VERSION ""

NS_ :

BS_:

BU_:

BO_ 2183149062 HeadLight_3606: 8 Vector__XXX
 SG_ HeadLightOn : 15|8@0+ (1,0) [0|0] "" Vector__XXX
 SG_ HeadLightSource : 7|8@0+ (1,0) [0|0] "" Vector__XXX

BO_ 2182616582 RearLight_1606: 8 Vector__XXX
 SG_ RearLightOn : 39|8@0+ (1,0) [0|0] "" Vector__XXX
 SG_ RearLightUnknownByte2 : 23|8@0+ (1,0) [0|0] "" Vector__XXX

BO_ 2478269440 Lock_6400: 1 Vector__XXX
 SG_ Unlocked : 7|8@0+ (1,0) [0|0] "" Vector__XXX

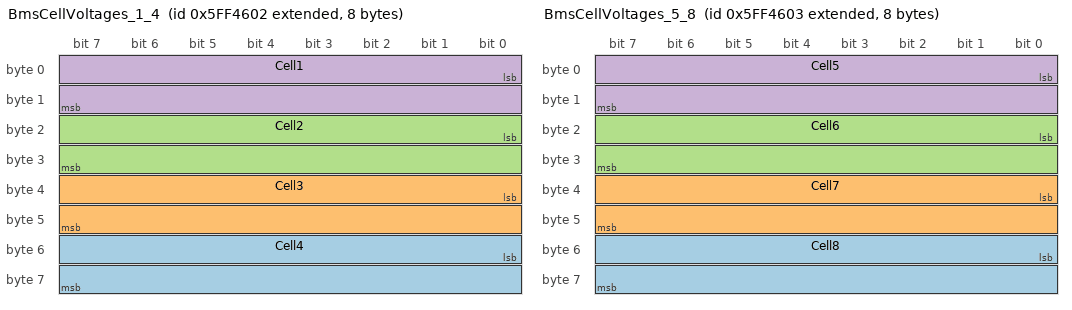
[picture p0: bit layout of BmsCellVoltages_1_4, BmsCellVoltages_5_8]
BO_ 2248099330 BmsCellVoltages_1_4: 8 Vector__XXX
 SG_ Cell4 : 48|16@1+ (1,0) [0|0] "mV" Vector__XXX
 SG_ Cell3 : 32|16@1+ (1,0) [0|0] "mV" Vector__XXX
 SG_ Cell2 : 16|16@1+ (1,0) [0|0] "mV" Vector__XXX
 SG_ Cell1 : 0|16@1+ (1,0) [0|0] "mV" Vector__XXX

BO_ 2248099331 BmsCellVoltages_5_8: 8 Vector__XXX
 SG_ Cell8 : 48|16@1+ (1,0) [0|0] "mV" Vector__XXX
 SG_ Cell7 : 32|16@1+ (1,0) [0|0] "mV" Vector__XXX
 SG_ Cell6 : 16|16@1+ (1,0) [0|0] "mV" Vector__XXX
 SG_ Cell5 : 0|16@1+ (1,0) [0|0] "mV" Vector__XXX

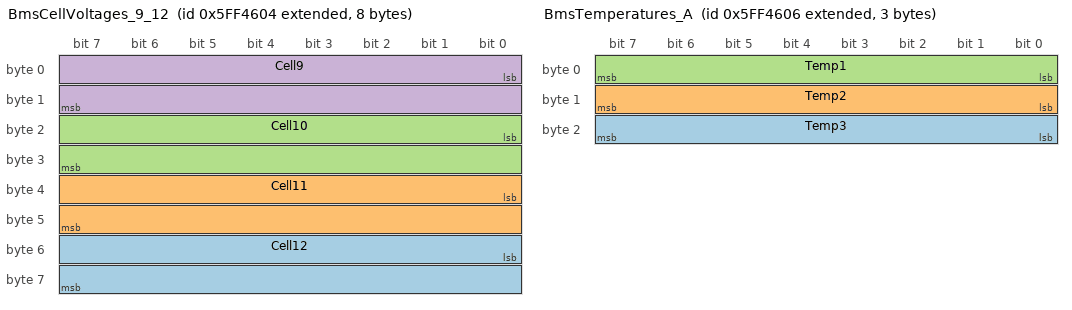
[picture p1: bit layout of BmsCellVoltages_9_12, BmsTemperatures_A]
BO_ 2248099332 BmsCellVoltages_9_12: 8 Vector__XXX
 SG_ Cell12 : 48|16@1+ (1,0) [0|0] "mV" Vector__XXX
 SG_ Cell11 : 32|16@1+ (1,0) [0|0] "mV" Vector__XXX
 SG_ Cell10 : 16|16@1+ (1,0) [0|0] "mV" Vector__XXX
 SG_ Cell9 : 0|16@1+ (1,0) [0|0] "mV" Vector__XXX

BO_ 2248099333 BmsCellVoltage_13: 8 Vector__XXX
 SG_ Cell13 : 0|16@1+ (1,0) [0|0] "mV" Vector__XXX

BO_ 2248099334 BmsTemperatures_A: 3 Vector__XXX
 SG_ Temp3 : 23|8@0+ (1,0) [0|0] "degC" Vector__XXX
 SG_ Temp2 : 15|8@0+ (1,0) [0|0] "degC" Vector__XXX
 SG_ Temp1 : 7|8@0+ (1,0) [0|0] "degC" Vector__XXX

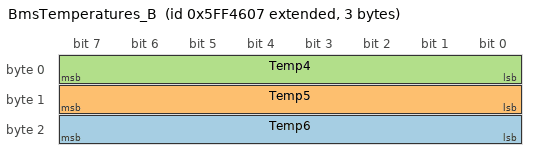
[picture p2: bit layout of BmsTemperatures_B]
BO_ 2248099335 BmsTemperatures_B: 3 Vector__XXX
 SG_ Temp6 : 23|8@0+ (1,0) [0|0] "degC" Vector__XXX
 SG_ Temp5 : 15|8@0+ (1,0) [0|0] "degC" Vector__XXX
 SG_ Temp4 : 7|8@0+ (1,0) [0|0] "degC" Vector__XXX

BO_ 2231317504 Uptime_3400: 8 Vector__XXX
 SG_ Uptime : 23|16@0+ (10,0) [0|0] "s" Vector__XXX

BO_ 2214531072 Heartbeat_1000: 8 Vector__XXX

CM_ BO_ 2183149062 "[confirmed] The headlight. Identified by remote command: the console logged HLON at
1788785214.368 and HLOFF at 1788785234.208, and this message changed 0.77 s and
0.33 s later respectively. Nothing else on the bus changed in either window
except the uptime counter ticking.";
CM_ SG_ 2183149062 HeadLightOn "[confirmed] Byte 1. Goes to 1 within 0.77 s of the HLON command and to 0 within 0.33 s of
HLOFF, then to 1 again 2.0 s after UNLOCK and to 0 1.3 s after LOCK -- so
unlocking the bike switches the headlight on, which is why the periodic GTFRI
report still showed head_light_status=1 after HLOFF. Cross-checks against
<ECU Info> field 5 (Head Light Status) in the same session.";
CM_ SG_ 2183149062 HeadLightSource "[hypothesis] Byte 0 is 0x02 when the change came from an explicit HLON/HLOFF command and
0x01 when it came from the unlock sequence, so it may say what asked for the
change. Two observations of each: nowhere near enough.";
CM_ BO_ 2182616582 "[confirmed] The rear light. Same method as the headlight: RLONEN at 1788785392.364 and
RLOFF at 1788785412.125, with this message changing 0.76 s and 0.40 s later,
and nothing else changing in either window.";
CM_ SG_ 2182616582 RearLightOn "[confirmed] Byte 4. Goes to 1 within 0.76 s of RLONEN and to 0 within 0.40 s of RLOFF, and
also tracks UNLOCK (0.28 s) and LOCK (0.52 s). Cross-checks against <ECU Info>
field 6 (Rear Light Status).";
CM_ SG_ 2182616582 RearLightUnknownByte2 "[hypothesis] Byte 2 is 0x19 (25) while the rear light is on because of an unlock, but 0x00
when it is on because of an RLONEN command. So it is not the light state. A
brightness or mode, possibly. Untested.";
CM_ BO_ 2478269440 "[confirmed] The lock (immobiliser) reporting its state. A single-byte message, and the only
one on the bus with priority 0x13.

Identified across two independent sessions by driving UNLOCK and LOCK remotely
and watching which byte tracked the resulting state. Method: build the lock
state timeline from the +RESP:GTMLS reports, then look for bytes whose value
sets are disjoint between locked and unlocked intervals. Exactly one byte
qualified across 2 locked and 2 unlocked intervals.

CONFIRMED BY DISCONNECTION: a third session was recorded with the HubLock
disabled. This identifier went from 139 frames to zero, and it was the ONLY
identifier to disappear -- 95 identifiers became 94, with none appearing in its
place. Both lamps still toggled normally in that session, so the bus was
healthy and the remote commands were still being processed. The component that
sends this is therefore the HubLock, and AA=0x64 is its address.

NOT the battery lock. <ECU Info> field 13 (Battery-Lock State) stayed 0 through
all three sessions while this byte flipped.";
CM_ SG_ 2478269440 Unlocked "[confirmed] Byte 0. 1 = unlocked, 0 = locked -- note this is the inverse of GTFRI's
ECU Lock State field, so it reads as an \"unlocked\" flag. Named for what the
raw value means rather than inverting it here.

Six transitions across two sessions, every one following its command:
  UNLOCK -> 1 after 2.12 s, 2.55 s, 2.17 s
  LOCK   -> 0 after 0.32 s, 0.46 s, 0.58 s
The asymmetry is consistent and worth keeping: unlocking takes about four times
as long as locking, which is what a motorised latch does and is not what a
command echo would do.

Repeated UNLOCK commands on an already-unlocked bike produce no transition, so
this byte reports actual state and not command receipt. That is why session 2's
six UNLOCK commands yielded only two unlock transitions.

DO NOT use GTFRI's ECU Lock State as a substitute for this signal. With the
HubLock disabled and no 13B76400 on the bus at all, that field still reported
lock_state flipping 0 and 1, so it tracks what the IoT module believes rather
than what the lock did.";
CM_ BO_ 2248099330 "[confirmed] BMS cell voltages, cells 1-4. Confirmed without guesswork: the +RESP:GTBMI
report relays this frame's payload verbatim -- the identical byte string
1410191019101910 appears both in the CAN payload and in the report -- and
GTBMI states a cell count of 13, which is exactly what 05FF4602 through
05FF4605 supply (4+4+4+1). The 13 cells sum to 53.622 V against the 53.696 V
that GTFRI reported for the pack at the same moment, a 0.14 % difference.";
CM_ SG_ 2248099330 Cell4 "[confirmed] Little-endian uint16 in mV.";
CM_ SG_ 2248099330 Cell3 "[confirmed] Little-endian uint16 in mV.";
CM_ SG_ 2248099330 Cell2 "[confirmed] Little-endian uint16 in mV.";
CM_ SG_ 2248099330 Cell1 "[confirmed] Little-endian uint16 in mV: bytes 14 10 read as 0x1014 = 4116 mV.";
CM_ BO_ 2248099331 "[confirmed] BMS cell voltages, cells 5-8. Relayed verbatim in +RESP:GTBMI.";
CM_ SG_ 2248099331 Cell8 "[confirmed] Little-endian uint16 in mV.";
CM_ SG_ 2248099331 Cell7 "[confirmed] Little-endian uint16 in mV.";
CM_ SG_ 2248099331 Cell6 "[confirmed] Little-endian uint16 in mV.";
CM_ SG_ 2248099331 Cell5 "[confirmed] Little-endian uint16 in mV.";
CM_ BO_ 2248099332 "[confirmed] BMS cell voltages, cells 9-12. Relayed verbatim in +RESP:GTBMI.";
CM_ SG_ 2248099332 Cell12 "[confirmed] Little-endian uint16 in mV.";
CM_ SG_ 2248099332 Cell11 "[confirmed] Little-endian uint16 in mV.";
CM_ SG_ 2248099332 Cell10 "[confirmed] Little-endian uint16 in mV.";
CM_ SG_ 2248099332 Cell9 "[confirmed] Little-endian uint16 in mV.";
CM_ BO_ 2248099333 "[confirmed] BMS cell voltage, cell 13, then padding. This pack has 13 cells, so the last
frame of the series carries one value and six zero bytes -- which is how the
cell count was established.";
CM_ SG_ 2248099333 Cell13 "[confirmed] Little-endian uint16 in mV. Bytes 2-7 are always zero: only 13 cells.";
CM_ BO_ 2248099334 "[probable] BMS temperatures. Payload 1C1C1C reads as 28, 28, 28 which is a plausible cell
temperature in degrees Celsius, and the same byte string is relayed in
+RESP:GTBMI immediately after the cell voltage frames. Which physical sensor
each byte is has not been established: <ECU Info> field 12 lists cell maximum,
cell minimum, MOS and \"other\" temperatures, and there are more of those than
there are bytes here.";
CM_ SG_ 2248099334 Temp3 "[probable] 0x1C = 28 degC. Sensor identity unknown.";
CM_ SG_ 2248099334 Temp2 "[probable] 0x1C = 28 degC. Sensor identity unknown.";
CM_ SG_ 2248099334 Temp1 "[probable] 0x1C = 28 degC. Sensor identity unknown; the scale may also have an offset.";
CM_ BO_ 2248099335 "[probable] More BMS temperatures: 1D1B1C reads as 29, 27, 28 degC, and is likewise
relayed verbatim in +RESP:GTBMI. The spread across the two frames is 27-29 degC
on a stationary bike at room temperature, which is what makes the reading
plausible.";
CM_ SG_ 2248099335 Temp6 "[probable] 0x1C = 28 degC. Sensor identity unknown.";
CM_ SG_ 2248099335 Temp5 "[probable] 0x1B = 27 degC. Sensor identity unknown.";
CM_ SG_ 2248099335 Temp4 "[probable] 0x1D = 29 degC. Sensor identity unknown.";
CM_ BO_ 2231317504 "[confirmed] A 10-second uptime tick. Bytes 0-1 and 4-7 are always zero; bytes 2-3 rise
monotonically and never repeat, so every frame of this message is unique.";
CM_ SG_ 2231317504 Uptime "[confirmed] CONFIRMED -- the rate. In the 4 September corpus the field's change between
consecutive frames equalled the elapsed wall-clock time divided by 10, exactly,
at all 76 steps, including across a 2520 s gap that advanced it by 252. The
7 September session reproduced this independently: 706 steps, every delta
exactly 1, against 7060 s elapsed. Wall-clock time is the ground truth, so the
scale needs no further test.

CONFIRMED -- that it is uptime, not an odometer. The field read 2878 when the
4 September session ended and 509 when the 7 September session began, so it
resets. A power-cycle test was recorded in signals.toml as the way to tell
uptime from an odometer, and this is that test passing.

CONFIRMED -- wider than 10 bits. discover.candidate_fields() reports only the
low 10 bits as active within one session, but the 7 September session ran the
field from 509 to 1215, straight past the 1023 where a 10-bit field would wrap,
monotonically and with every delta 1.

UNKNOWN -- whether it is 16 or 32 bits. Bytes 0-1 are always zero, so they
could be the high half of a 32-bit value. Separating the two needs more than
7.6 days of continuous uptime, which is when a 16-bit field would wrap.

UNKNOWN -- which component sends it, and what event starts the count.";
CM_ BO_ 2214531072 "[probable] A heartbeat. 7243 of the 7588 frames in the 4 September corpus, every 105 ms,
payload 0840112200000001, which never varies once. A fixed payload at a fixed
rate carries no information, so no signals are defined. Node field 10->00
appears nowhere else.";
BA_DEF_ BO_  "GenMsgCycleTime" INT 0 65535;
BA_DEF_DEF_  "GenMsgCycleTime" 0;
BA_ "GenMsgCycleTime" BO_ 2478269440 280;
BA_ "GenMsgCycleTime" BO_ 2248099330 1044;
BA_ "GenMsgCycleTime" BO_ 2248099331 1044;
BA_ "GenMsgCycleTime" BO_ 2248099332 1044;
BA_ "GenMsgCycleTime" BO_ 2248099333 1044;
BA_ "GenMsgCycleTime" BO_ 2248099334 1044;
BA_ "GenMsgCycleTime" BO_ 2248099335 1044;
BA_ "GenMsgCycleTime" BO_ 2231317504 10000;
BA_ "GenMsgCycleTime" BO_ 2214531072 105;
